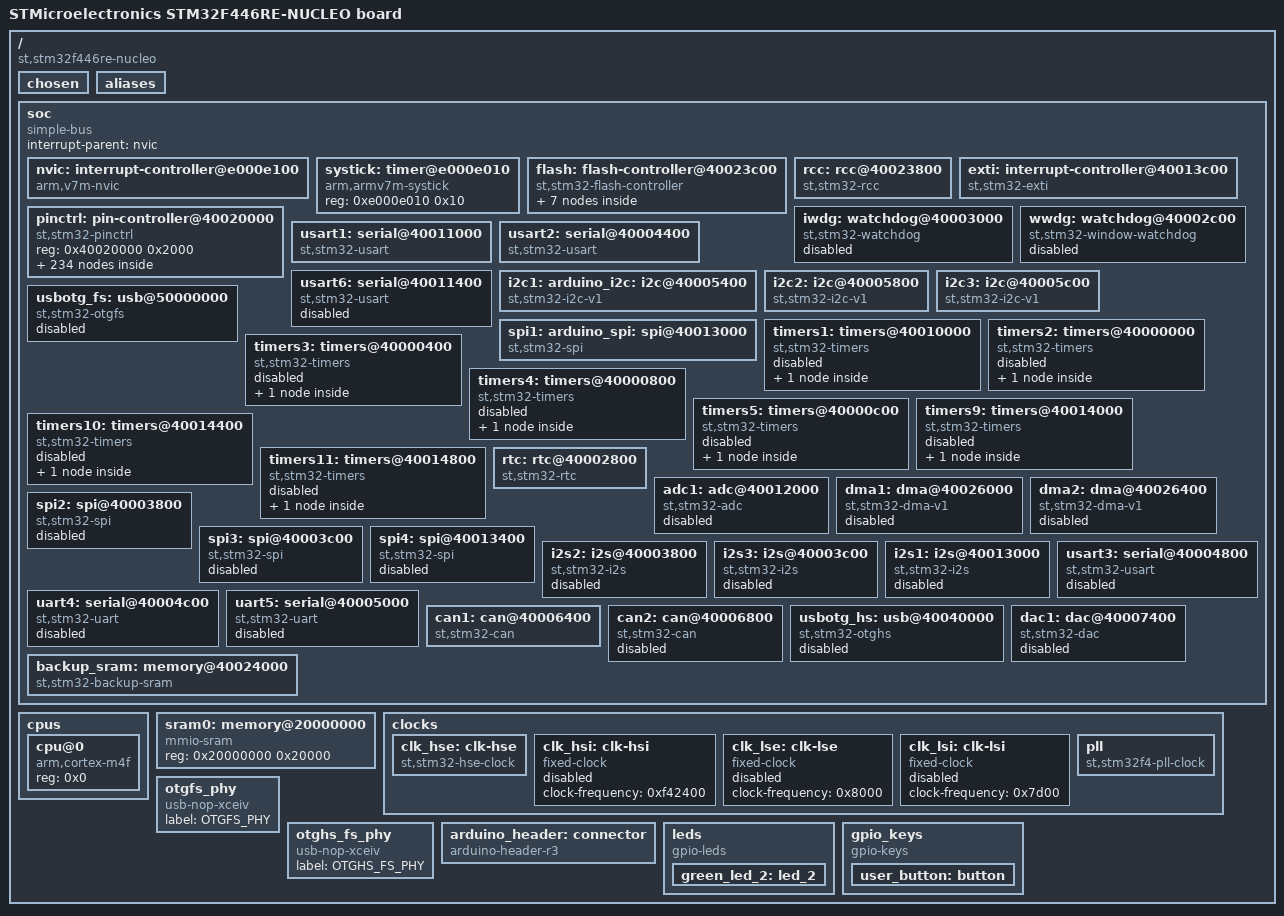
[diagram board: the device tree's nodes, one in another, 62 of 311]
/dts-v1/;

/ {
	#address-cells = < 0x1 >;
	#size-cells = < 0x1 >;
	model = "STMicroelectronics STM32F446RE-NUCLEO board";
	compatible = "st,stm32f446re-nucleo";
	chosen {
		zephyr,flash-controller = &flash;
		zephyr,console = &usart2;
		zephyr,shell-uart = &usart2;
		zephyr,sram = &sram0;
		zephyr,flash = &flash0;
		zephyr,can-primary = &can1;
	};
	aliases {
		led0 = &green_led_2;
		sw0 = &user_button;
	};
	soc {
		#address-cells = < 0x1 >;
		#size-cells = < 0x1 >;
		compatible = "simple-bus";
		interrupt-parent = < &nvic >;
		ranges;
		nvic: interrupt-controller@e000e100 {
			compatible = "arm,v7m-nvic";
			reg = < 0xe000e100 0xc00 >;
			interrupt-controller;
			#interrupt-cells = < 0x2 >;
			arm,num-irq-priority-bits = < 0x4 >;
			phandle = < 0x1 >;
		};
		systick: timer@e000e010 {
			compatible = "arm,armv7m-systick";
			reg = < 0xe000e010 0x10 >;
		};
		flash: flash-controller@40023c00 {
			compatible = "st,stm32-flash-controller", "st,stm32f4-flash-controller";
			label = "FLASH_CTRL";
			reg = < 0x40023c00 0x400 >;
			interrupts = < 0x4 0x0 >;
			#address-cells = < 0x1 >;
			#size-cells = < 0x1 >;
			flash0: flash@8000000 {
				compatible = "soc-nv-flash";
				label = "FLASH_STM32";
				write-block-size = < 0x1 >;
				reg = < 0x8000000 0x80000 >;
				partitions {
					compatible = "fixed-partitions";
					#address-cells = < 0x1 >;
					#size-cells = < 0x1 >;
					boot_partition: partition@0 {
						label = "mcuboot";
						reg = < 0x0 0x10000 >;
						read-only;
					};
					storage_partition: partition@10000 {
						label = "storage";
						reg = < 0x10000 0x10000 >;
					};
					slot0_partition: partition@20000 {
						label = "image-0";
						reg = < 0x20000 0x20000 >;
					};
					slot1_partition: partition@40000 {
						label = "image-1";
						reg = < 0x40000 0x20000 >;
					};
					scratch_partition: partition@60000 {
						label = "image-scratch";
						reg = < 0x60000 0x20000 >;
					};
				};
			};
		};
		rcc: rcc@40023800 {
			compatible = "st,stm32-rcc";
			#clock-cells = < 0x2 >;
			reg = < 0x40023800 0x400 >;
			clocks = < &pll >;
			clock-frequency = < 0x5b8d800 >;
			ahb-prescaler = < 0x1 >;
			apb1-prescaler = < 0x2 >;
			apb2-prescaler = < 0x1 >;
			phandle = < 0x3 >;
		};
		exti: interrupt-controller@40013c00 {
			compatible = "st,stm32-exti";
			interrupt-controller;
			#interrupt-cells = < 0x1 >;
			reg = < 0x40013c00 0x400 >;
		};
		pinctrl: pin-controller@40020000 {
			compatible = "st,stm32-pinctrl";
			#address-cells = < 0x1 >;
			#size-cells = < 0x1 >;
			reg = < 0x40020000 0x2000 >;
			gpioa: gpio@40020000 {
				compatible = "st,stm32-gpio";
				gpio-controller;
				#gpio-cells = < 0x2 >;
				reg = < 0x40020000 0x400 >;
				clocks = < &rcc 0x0 0x1 >;
				label = "GPIOA";
				phandle = < 0x1a >;
			};
			gpiob: gpio@40020400 {
				compatible = "st,stm32-gpio";
				gpio-controller;
				#gpio-cells = < 0x2 >;
				reg = < 0x40020400 0x400 >;
				clocks = < &rcc 0x0 0x2 >;
				label = "GPIOB";
				phandle = < 0xe >;
			};
			gpioc: gpio@40020800 {
				compatible = "st,stm32-gpio";
				gpio-controller;
				#gpio-cells = < 0x2 >;
				reg = < 0x40020800 0x400 >;
				clocks = < &rcc 0x0 0x4 >;
				label = "GPIOC";
				phandle = < 0x1b >;
			};
			gpiod: gpio@40020c00 {
				compatible = "st,stm32-gpio";
				gpio-controller;
				#gpio-cells = < 0x2 >;
				reg = < 0x40020c00 0x400 >;
				clocks = < &rcc 0x0 0x8 >;
				label = "GPIOD";
			};
			gpioe: gpio@40021000 {
				compatible = "st,stm32-gpio";
				gpio-controller;
				#gpio-cells = < 0x2 >;
				reg = < 0x40021000 0x400 >;
				clocks = < &rcc 0x0 0x10 >;
				label = "GPIOE";
			};
			gpioh: gpio@40021c00 {
				compatible = "st,stm32-gpio";
				gpio-controller;
				#gpio-cells = < 0x2 >;
				reg = < 0x40021c00 0x400 >;
				clocks = < &rcc 0x0 0x80 >;
				label = "GPIOH";
			};
			adc1_in0_pa0: adc1_in0_pa0 {
				pinmux = < 0x10 >;
			};
			adc1_in1_pa1: adc1_in1_pa1 {
				pinmux = < 0x110 >;
			};
			adc1_in2_pa2: adc1_in2_pa2 {
				pinmux = < 0x210 >;
			};
			adc1_in3_pa3: adc1_in3_pa3 {
				pinmux = < 0x310 >;
			};
			adc1_in4_pa4: adc1_in4_pa4 {
				pinmux = < 0x410 >;
			};
			adc1_in5_pa5: adc1_in5_pa5 {
				pinmux = < 0x510 >;
			};
			adc1_in6_pa6: adc1_in6_pa6 {
				pinmux = < 0x610 >;
			};
			adc1_in7_pa7: adc1_in7_pa7 {
				pinmux = < 0x710 >;
			};
			adc1_in8_pb0: adc1_in8_pb0 {
				pinmux = < 0x1010 >;
			};
			adc1_in9_pb1: adc1_in9_pb1 {
				pinmux = < 0x1110 >;
			};
			adc1_in10_pc0: adc1_in10_pc0 {
				pinmux = < 0x2010 >;
			};
			adc1_in11_pc1: adc1_in11_pc1 {
				pinmux = < 0x2110 >;
			};
			adc1_in12_pc2: adc1_in12_pc2 {
				pinmux = < 0x2210 >;
			};
			adc1_in13_pc3: adc1_in13_pc3 {
				pinmux = < 0x2310 >;
			};
			adc1_in14_pc4: adc1_in14_pc4 {
				pinmux = < 0x2410 >;
			};
			adc1_in15_pc5: adc1_in15_pc5 {
				pinmux = < 0x2510 >;
			};
			adc2_in0_pa0: adc2_in0_pa0 {
				pinmux = < 0x10 >;
			};
			adc2_in1_pa1: adc2_in1_pa1 {
				pinmux = < 0x110 >;
			};
			adc2_in2_pa2: adc2_in2_pa2 {
				pinmux = < 0x210 >;
			};
			adc2_in3_pa3: adc2_in3_pa3 {
				pinmux = < 0x310 >;
			};
			adc2_in4_pa4: adc2_in4_pa4 {
				pinmux = < 0x410 >;
			};
			adc2_in5_pa5: adc2_in5_pa5 {
				pinmux = < 0x510 >;
			};
			adc2_in6_pa6: adc2_in6_pa6 {
				pinmux = < 0x610 >;
			};
			adc2_in7_pa7: adc2_in7_pa7 {
				pinmux = < 0x710 >;
			};
			adc2_in8_pb0: adc2_in8_pb0 {
				pinmux = < 0x1010 >;
			};
			adc2_in9_pb1: adc2_in9_pb1 {
				pinmux = < 0x1110 >;
			};
			adc2_in10_pc0: adc2_in10_pc0 {
				pinmux = < 0x2010 >;
			};
			adc2_in11_pc1: adc2_in11_pc1 {
				pinmux = < 0x2110 >;
			};
			adc2_in12_pc2: adc2_in12_pc2 {
				pinmux = < 0x2210 >;
			};
			adc2_in13_pc3: adc2_in13_pc3 {
				pinmux = < 0x2310 >;
			};
			adc2_in14_pc4: adc2_in14_pc4 {
				pinmux = < 0x2410 >;
			};
			adc2_in15_pc5: adc2_in15_pc5 {
				pinmux = < 0x2510 >;
			};
			adc3_in0_pa0: adc3_in0_pa0 {
				pinmux = < 0x10 >;
			};
			adc3_in1_pa1: adc3_in1_pa1 {
				pinmux = < 0x110 >;
			};
			adc3_in2_pa2: adc3_in2_pa2 {
				pinmux = < 0x210 >;
			};
			adc3_in3_pa3: adc3_in3_pa3 {
				pinmux = < 0x310 >;
			};
			adc3_in10_pc0: adc3_in10_pc0 {
				pinmux = < 0x2010 >;
			};
			adc3_in11_pc1: adc3_in11_pc1 {
				pinmux = < 0x2110 >;
			};
			adc3_in12_pc2: adc3_in12_pc2 {
				pinmux = < 0x2210 >;
			};
			adc3_in13_pc3: adc3_in13_pc3 {
				pinmux = < 0x2310 >;
			};
			can1_rx_pa11: can1_rx_pa11 {
				pinmux = < 0xb09 >;
				bias-pull-up;
			};
			can1_rx_pb8: can1_rx_pb8 {
				pinmux = < 0x1809 >;
				bias-pull-up;
				phandle = < 0x16 >;
			};
			can2_rx_pb5: can2_rx_pb5 {
				pinmux = < 0x1509 >;
				bias-pull-up;
			};
			can2_rx_pb12: can2_rx_pb12 {
				pinmux = < 0x1c09 >;
				bias-pull-up;
			};
			can1_tx_pa12: can1_tx_pa12 {
				pinmux = < 0xc09 >;
			};
			can1_tx_pb9: can1_tx_pb9 {
				pinmux = < 0x1909 >;
				phandle = < 0x17 >;
			};
			can2_tx_pb6: can2_tx_pb6 {
				pinmux = < 0x1609 >;
			};
			can2_tx_pb13: can2_tx_pb13 {
				pinmux = < 0x1d09 >;
			};
			dac_out1_pa4: dac_out1_pa4 {
				pinmux = < 0x410 >;
			};
			dac_out2_pa5: dac_out2_pa5 {
				pinmux = < 0x510 >;
			};
			i2c1_scl_pb6: i2c1_scl_pb6 {
				pinmux = < 0x1604 >;
				bias-pull-up;
				drive-open-drain;
			};
			i2c1_scl_pb8: i2c1_scl_pb8 {
				pinmux = < 0x1804 >;
				bias-pull-up;
				drive-open-drain;
				phandle = < 0x8 >;
			};
			i2c2_scl_pb10: i2c2_scl_pb10 {
				pinmux = < 0x1a04 >;
				bias-pull-up;
				drive-open-drain;
				phandle = < 0xa >;
			};
			i2c3_scl_pa8: i2c3_scl_pa8 {
				pinmux = < 0x804 >;
				bias-pull-up;
				drive-open-drain;
				phandle = < 0xc >;
			};
			i2c1_sda_pb7: i2c1_sda_pb7 {
				pinmux = < 0x1704 >;
				bias-pull-up;
				drive-open-drain;
			};
			i2c1_sda_pb9: i2c1_sda_pb9 {
				pinmux = < 0x1904 >;
				bias-pull-up;
				drive-open-drain;
				phandle = < 0x9 >;
			};
			i2c2_sda_pb3: i2c2_sda_pb3 {
				pinmux = < 0x1304 >;
				bias-pull-up;
				drive-open-drain;
				phandle = < 0xb >;
			};
			i2c2_sda_pc12: i2c2_sda_pc12 {
				pinmux = < 0x2c04 >;
				bias-pull-up;
				drive-open-drain;
			};
			i2c3_sda_pb4: i2c3_sda_pb4 {
				pinmux = < 0x1404 >;
				bias-pull-up;
				drive-open-drain;
				phandle = < 0xd >;
			};
			i2c3_sda_pc9: i2c3_sda_pc9 {
				pinmux = < 0x2904 >;
				bias-pull-up;
				drive-open-drain;
			};
			i2s1_ck_pa5: i2s1_ck_pa5 {
				pinmux = < 0x505 >;
				slew-rate = "very-high-speed";
			};
			i2s1_ck_pb3: i2s1_ck_pb3 {
				pinmux = < 0x1305 >;
				slew-rate = "very-high-speed";
			};
			i2s2_ck_pa9: i2s2_ck_pa9 {
				pinmux = < 0x905 >;
				slew-rate = "very-high-speed";
			};
			i2s2_ck_pb10: i2s2_ck_pb10 {
				pinmux = < 0x1a05 >;
				slew-rate = "very-high-speed";
			};
			i2s2_ck_pb13: i2s2_ck_pb13 {
				pinmux = < 0x1d05 >;
				slew-rate = "very-high-speed";
			};
			i2s2_ck_pc7: i2s2_ck_pc7 {
				pinmux = < 0x2705 >;
				slew-rate = "very-high-speed";
			};
			i2s3_ck_pb3: i2s3_ck_pb3 {
				pinmux = < 0x1306 >;
				slew-rate = "very-high-speed";
			};
			i2s3_ck_pc10: i2s3_ck_pc10 {
				pinmux = < 0x2a06 >;
				slew-rate = "very-high-speed";
			};
			i2s1_sd_pa7: i2s1_sd_pa7 {
				pinmux = < 0x705 >;
			};
			i2s1_sd_pb5: i2s1_sd_pb5 {
				pinmux = < 0x1505 >;
			};
			i2s2_sd_pb15: i2s2_sd_pb15 {
				pinmux = < 0x1f05 >;
			};
			i2s2_sd_pc1: i2s2_sd_pc1 {
				pinmux = < 0x2107 >;
			};
			i2s2_sd_pc3: i2s2_sd_pc3 {
				pinmux = < 0x2305 >;
			};
			i2s3_sd_pb0: i2s3_sd_pb0 {
				pinmux = < 0x1007 >;
			};
			i2s3_sd_pb2: i2s3_sd_pb2 {
				pinmux = < 0x1207 >;
			};
			i2s3_sd_pb5: i2s3_sd_pb5 {
				pinmux = < 0x1506 >;
			};
			i2s3_sd_pc1: i2s3_sd_pc1 {
				pinmux = < 0x2105 >;
			};
			i2s3_sd_pc12: i2s3_sd_pc12 {
				pinmux = < 0x2c06 >;
			};
			i2s1_ws_pa4: i2s1_ws_pa4 {
				pinmux = < 0x405 >;
			};
			i2s1_ws_pa15: i2s1_ws_pa15 {
				pinmux = < 0xf05 >;
			};
			i2s2_ws_pb4: i2s2_ws_pb4 {
				pinmux = < 0x1407 >;
			};
			i2s2_ws_pb9: i2s2_ws_pb9 {
				pinmux = < 0x1905 >;
			};
			i2s2_ws_pb12: i2s2_ws_pb12 {
				pinmux = < 0x1c05 >;
			};
			i2s3_ws_pa4: i2s3_ws_pa4 {
				pinmux = < 0x406 >;
			};
			i2s3_ws_pa15: i2s3_ws_pa15 {
				pinmux = < 0xf06 >;
			};
			quadspi_bk1_io3_pa1: quadspi_bk1_io3_pa1 {
				pinmux = < 0x109 >;
				slew-rate = "very-high-speed";
			};
			quadspi_clk_pb2: quadspi_clk_pb2 {
				pinmux = < 0x1209 >;
				slew-rate = "very-high-speed";
			};
			quadspi_bk1_ncs_pb6: quadspi_bk1_ncs_pb6 {
				pinmux = < 0x160a >;
				slew-rate = "very-high-speed";
			};
			quadspi_bk1_io0_pc9: quadspi_bk1_io0_pc9 {
				pinmux = < 0x2909 >;
				slew-rate = "very-high-speed";
			};
			quadspi_bk1_io1_pc10: quadspi_bk1_io1_pc10 {
				pinmux = < 0x2a09 >;
				slew-rate = "very-high-speed";
			};
			quadspi_bk2_ncs_pc11: quadspi_bk2_ncs_pc11 {
				pinmux = < 0x2b09 >;
				slew-rate = "very-high-speed";
			};
			spi1_miso_pa6: spi1_miso_pa6 {
				pinmux = < 0x605 >;
				bias-pull-down;
				phandle = < 0x11 >;
			};
			spi1_miso_pb4: spi1_miso_pb4 {
				pinmux = < 0x1405 >;
				bias-pull-down;
			};
			spi2_miso_pb14: spi2_miso_pb14 {
				pinmux = < 0x1e05 >;
				bias-pull-down;
			};
			spi2_miso_pc2: spi2_miso_pc2 {
				pinmux = < 0x2205 >;
				bias-pull-down;
			};
			spi3_miso_pb4: spi3_miso_pb4 {
				pinmux = < 0x1406 >;
				bias-pull-down;
			};
			spi3_miso_pc11: spi3_miso_pc11 {
				pinmux = < 0x2b06 >;
				bias-pull-down;
			};
			spi1_mosi_pa7: spi1_mosi_pa7 {
				pinmux = < 0x705 >;
				bias-pull-down;
				phandle = < 0x12 >;
			};
			spi1_mosi_pb5: spi1_mosi_pb5 {
				pinmux = < 0x1505 >;
				bias-pull-down;
			};
			spi2_mosi_pb15: spi2_mosi_pb15 {
				pinmux = < 0x1f05 >;
				bias-pull-down;
			};
			spi2_mosi_pc1: spi2_mosi_pc1 {
				pinmux = < 0x2107 >;
				bias-pull-down;
			};
			spi2_mosi_pc3: spi2_mosi_pc3 {
				pinmux = < 0x2305 >;
				bias-pull-down;
			};
			spi3_mosi_pb0: spi3_mosi_pb0 {
				pinmux = < 0x1007 >;
				bias-pull-down;
			};
			spi3_mosi_pb2: spi3_mosi_pb2 {
				pinmux = < 0x1207 >;
				bias-pull-down;
			};
			spi3_mosi_pb5: spi3_mosi_pb5 {
				pinmux = < 0x1506 >;
				bias-pull-down;
			};
			spi3_mosi_pc1: spi3_mosi_pc1 {
				pinmux = < 0x2105 >;
				bias-pull-down;
			};
			spi3_mosi_pc12: spi3_mosi_pc12 {
				pinmux = < 0x2c06 >;
				bias-pull-down;
			};
			spi1_nss_pa4: spi1_nss_pa4 {
				pinmux = < 0x405 >;
				bias-pull-up;
				phandle = < 0xf >;
			};
			spi1_nss_pa15: spi1_nss_pa15 {
				pinmux = < 0xf05 >;
				bias-pull-up;
			};
			spi2_nss_pb4: spi2_nss_pb4 {
				pinmux = < 0x1407 >;
				bias-pull-up;
			};
			spi2_nss_pb9: spi2_nss_pb9 {
				pinmux = < 0x1905 >;
				bias-pull-up;
			};
			spi2_nss_pb12: spi2_nss_pb12 {
				pinmux = < 0x1c05 >;
				bias-pull-up;
			};
			spi3_nss_pa4: spi3_nss_pa4 {
				pinmux = < 0x406 >;
				bias-pull-up;
			};
			spi3_nss_pa15: spi3_nss_pa15 {
				pinmux = < 0xf06 >;
				bias-pull-up;
			};
			spi1_sck_pa5: spi1_sck_pa5 {
				pinmux = < 0x505 >;
				bias-pull-down;
				slew-rate = "very-high-speed";
				phandle = < 0x10 >;
			};
			spi1_sck_pb3: spi1_sck_pb3 {
				pinmux = < 0x1305 >;
				bias-pull-down;
				slew-rate = "very-high-speed";
			};
			spi2_sck_pa9: spi2_sck_pa9 {
				pinmux = < 0x905 >;
				bias-pull-down;
				slew-rate = "very-high-speed";
			};
			spi2_sck_pb10: spi2_sck_pb10 {
				pinmux = < 0x1a05 >;
				bias-pull-down;
				slew-rate = "very-high-speed";
			};
			spi2_sck_pb13: spi2_sck_pb13 {
				pinmux = < 0x1d05 >;
				bias-pull-down;
				slew-rate = "very-high-speed";
			};
			spi2_sck_pc7: spi2_sck_pc7 {
				pinmux = < 0x2705 >;
				bias-pull-down;
				slew-rate = "very-high-speed";
			};
			spi3_sck_pb3: spi3_sck_pb3 {
				pinmux = < 0x1306 >;
				bias-pull-down;
				slew-rate = "very-high-speed";
			};
			spi3_sck_pc10: spi3_sck_pc10 {
				pinmux = < 0x2a06 >;
				bias-pull-down;
				slew-rate = "very-high-speed";
			};
			tim10_ch1_pb8: tim10_ch1_pb8 {
				pinmux = < 0x1803 >;
			};
			tim1_ch1n_pa7: tim1_ch1n_pa7 {
				pinmux = < 0x701 >;
			};
			tim1_ch1_pa8: tim1_ch1_pa8 {
				pinmux = < 0x801 >;
			};
			tim1_ch2_pa9: tim1_ch2_pa9 {
				pinmux = < 0x901 >;
			};
			tim1_ch3_pa10: tim1_ch3_pa10 {
				pinmux = < 0xa01 >;
			};
			tim1_ch4_pa11: tim1_ch4_pa11 {
				pinmux = < 0xb01 >;
			};
			tim1_ch2n_pb0: tim1_ch2n_pb0 {
				pinmux = < 0x1001 >;
			};
			tim1_ch3n_pb1: tim1_ch3n_pb1 {
				pinmux = < 0x1101 >;
			};
			tim11_ch1_pb9: tim11_ch1_pb9 {
				pinmux = < 0x1903 >;
			};
			tim1_ch1n_pb13: tim1_ch1n_pb13 {
				pinmux = < 0x1d01 >;
			};
			tim1_ch2n_pb14: tim1_ch2n_pb14 {
				pinmux = < 0x1e01 >;
			};
			tim1_ch3n_pb15: tim1_ch3n_pb15 {
				pinmux = < 0x1f01 >;
			};
			tim2_ch1_pa0: tim2_ch1_pa0 {
				pinmux = < 0x1 >;
			};
			tim2_ch2_pa1: tim2_ch2_pa1 {
				pinmux = < 0x101 >;
			};
			tim2_ch3_pa2: tim2_ch3_pa2 {
				pinmux = < 0x201 >;
			};
			tim2_ch4_pa3: tim2_ch4_pa3 {
				pinmux = < 0x301 >;
			};
			tim2_ch1_pa5: tim2_ch1_pa5 {
				pinmux = < 0x501 >;
			};
			tim2_ch1_pa15: tim2_ch1_pa15 {
				pinmux = < 0xf01 >;
			};
			tim2_ch4_pb2: tim2_ch4_pb2 {
				pinmux = < 0x1201 >;
			};
			tim2_ch2_pb3: tim2_ch2_pb3 {
				pinmux = < 0x1301 >;
			};
			tim2_ch1_pb8: tim2_ch1_pb8 {
				pinmux = < 0x1801 >;
			};
			tim2_ch2_pb9: tim2_ch2_pb9 {
				pinmux = < 0x1901 >;
			};
			tim2_ch3_pb10: tim2_ch3_pb10 {
				pinmux = < 0x1a01 >;
			};
			tim12_ch1_pb14: tim12_ch1_pb14 {
				pinmux = < 0x1e09 >;
			};
			tim12_ch2_pb15: tim12_ch2_pb15 {
				pinmux = < 0x1f09 >;
			};
			tim13_ch1_pa6: tim13_ch1_pa6 {
				pinmux = < 0x609 >;
			};
			tim3_ch1_pa6: tim3_ch1_pa6 {
				pinmux = < 0x602 >;
			};
			tim3_ch2_pa7: tim3_ch2_pa7 {
				pinmux = < 0x702 >;
			};
			tim3_ch3_pb0: tim3_ch3_pb0 {
				pinmux = < 0x1002 >;
			};
			tim3_ch4_pb1: tim3_ch4_pb1 {
				pinmux = < 0x1102 >;
			};
			tim3_ch1_pb4: tim3_ch1_pb4 {
				pinmux = < 0x1402 >;
			};
			tim3_ch2_pb5: tim3_ch2_pb5 {
				pinmux = < 0x1502 >;
			};
			tim3_ch1_pc6: tim3_ch1_pc6 {
				pinmux = < 0x2602 >;
			};
			tim3_ch2_pc7: tim3_ch2_pc7 {
				pinmux = < 0x2702 >;
			};
			tim3_ch3_pc8: tim3_ch3_pc8 {
				pinmux = < 0x2802 >;
			};
			tim3_ch4_pc9: tim3_ch4_pc9 {
				pinmux = < 0x2902 >;
			};
			tim14_ch1_pa7: tim14_ch1_pa7 {
				pinmux = < 0x709 >;
			};
			tim4_ch1_pb6: tim4_ch1_pb6 {
				pinmux = < 0x1602 >;
			};
			tim4_ch2_pb7: tim4_ch2_pb7 {
				pinmux = < 0x1702 >;
			};
			tim4_ch3_pb8: tim4_ch3_pb8 {
				pinmux = < 0x1802 >;
			};
			tim4_ch4_pb9: tim4_ch4_pb9 {
				pinmux = < 0x1902 >;
			};
			tim5_ch1_pa0: tim5_ch1_pa0 {
				pinmux = < 0x2 >;
			};
			tim5_ch2_pa1: tim5_ch2_pa1 {
				pinmux = < 0x102 >;
			};
			tim5_ch3_pa2: tim5_ch3_pa2 {
				pinmux = < 0x202 >;
			};
			tim5_ch4_pa3: tim5_ch4_pa3 {
				pinmux = < 0x302 >;
			};
			tim8_ch1n_pa5: tim8_ch1n_pa5 {
				pinmux = < 0x503 >;
			};
			tim8_ch1n_pa7: tim8_ch1n_pa7 {
				pinmux = < 0x703 >;
			};
			tim8_ch2n_pb0: tim8_ch2n_pb0 {
				pinmux = < 0x1003 >;
			};
			tim8_ch3n_pb1: tim8_ch3n_pb1 {
				pinmux = < 0x1103 >;
			};
			tim8_ch2n_pb14: tim8_ch2n_pb14 {
				pinmux = < 0x1e03 >;
			};
			tim8_ch3n_pb15: tim8_ch3n_pb15 {
				pinmux = < 0x1f03 >;
			};
			tim8_ch1_pc6: tim8_ch1_pc6 {
				pinmux = < 0x2603 >;
			};
			tim8_ch2_pc7: tim8_ch2_pc7 {
				pinmux = < 0x2703 >;
			};
			tim8_ch3_pc8: tim8_ch3_pc8 {
				pinmux = < 0x2803 >;
			};
			tim8_ch4_pc9: tim8_ch4_pc9 {
				pinmux = < 0x2903 >;
			};
			tim9_ch1_pa2: tim9_ch1_pa2 {
				pinmux = < 0x203 >;
			};
			tim9_ch2_pa3: tim9_ch2_pa3 {
				pinmux = < 0x303 >;
			};
			usart1_cts_pa11: usart1_cts_pa11 {
				pinmux = < 0xb07 >;
				bias-pull-up;
				drive-open-drain;
			};
			usart2_cts_pa0: usart2_cts_pa0 {
				pinmux = < 0x7 >;
				bias-pull-up;
				drive-open-drain;
			};
			usart3_cts_pb13: usart3_cts_pb13 {
				pinmux = < 0x1d07 >;
				bias-pull-up;
				drive-open-drain;
			};
			uart4_cts_pb0: uart4_cts_pb0 {
				pinmux = < 0x1008 >;
				bias-pull-up;
				drive-open-drain;
			};
			uart5_cts_pc9: uart5_cts_pc9 {
				pinmux = < 0x2907 >;
				bias-pull-up;
				drive-open-drain;
			};
			usart1_rts_pa12: usart1_rts_pa12 {
				pinmux = < 0xc07 >;
				bias-pull-up;
				drive-open-drain;
			};
			usart2_rts_pa1: usart2_rts_pa1 {
				pinmux = < 0x107 >;
				bias-pull-up;
				drive-open-drain;
			};
			usart3_rts_pb14: usart3_rts_pb14 {
				pinmux = < 0x1e07 >;
				bias-pull-up;
				drive-open-drain;
			};
			uart4_rts_pa15: uart4_rts_pa15 {
				pinmux = < 0xf08 >;
				bias-pull-up;
				drive-open-drain;
			};
			uart5_rts_pc8: uart5_rts_pc8 {
				pinmux = < 0x2807 >;
				bias-pull-up;
				drive-open-drain;
			};
			usart1_rx_pa10: usart1_rx_pa10 {
				pinmux = < 0xa07 >;
				phandle = < 0x5 >;
			};
			usart1_rx_pb7: usart1_rx_pb7 {
				pinmux = < 0x1707 >;
			};
			usart2_rx_pa3: usart2_rx_pa3 {
				pinmux = < 0x307 >;
				phandle = < 0x7 >;
			};
			usart3_rx_pc5: usart3_rx_pc5 {
				pinmux = < 0x2507 >;
			};
			usart3_rx_pc11: usart3_rx_pc11 {
				pinmux = < 0x2b07 >;
			};
			uart4_rx_pa1: uart4_rx_pa1 {
				pinmux = < 0x108 >;
			};
			uart4_rx_pc11: uart4_rx_pc11 {
				pinmux = < 0x2b08 >;
			};
			uart5_rx_pd2: uart5_rx_pd2 {
				pinmux = < 0x3208 >;
			};
			usart6_rx_pc7: usart6_rx_pc7 {
				pinmux = < 0x2708 >;
			};
			usart1_tx_pa9: usart1_tx_pa9 {
				pinmux = < 0x907 >;
				bias-pull-up;
				phandle = < 0x4 >;
			};
			usart1_tx_pb6: usart1_tx_pb6 {
				pinmux = < 0x1607 >;
				bias-pull-up;
			};
			usart2_tx_pa2: usart2_tx_pa2 {
				pinmux = < 0x207 >;
				bias-pull-up;
				phandle = < 0x6 >;
			};
			usart3_tx_pb10: usart3_tx_pb10 {
				pinmux = < 0x1a07 >;
				bias-pull-up;
			};
			usart3_tx_pc10: usart3_tx_pc10 {
				pinmux = < 0x2a07 >;
				bias-pull-up;
			};
			uart4_tx_pa0: uart4_tx_pa0 {
				pinmux = < 0x8 >;
				bias-pull-up;
			};
			uart4_tx_pc10: uart4_tx_pc10 {
				pinmux = < 0x2a08 >;
				bias-pull-up;
			};
			uart5_tx_pc12: uart5_tx_pc12 {
				pinmux = < 0x2c08 >;
				bias-pull-up;
			};
			usart6_tx_pc6: usart6_tx_pc6 {
				pinmux = < 0x2608 >;
				bias-pull-up;
			};
			usb_otg_fs_sof_pa8: usb_otg_fs_sof_pa8 {
				pinmux = < 0x80a >;
			};
			usb_otg_fs_vbus_pa9: usb_otg_fs_vbus_pa9 {
				pinmux = < 0x910 >;
			};
			usb_otg_fs_id_pa10: usb_otg_fs_id_pa10 {
				pinmux = < 0xa0a >;
			};
			usb_otg_fs_dm_pa11: usb_otg_fs_dm_pa11 {
				pinmux = < 0xb0a >;
			};
			usb_otg_fs_dp_pa12: usb_otg_fs_dp_pa12 {
				pinmux = < 0xc0a >;
			};
			usb_otg_hs_sof_pa4: usb_otg_hs_sof_pa4 {
				pinmux = < 0x40c >;
			};
			usb_otg_hs_id_pb12: usb_otg_hs_id_pb12 {
				pinmux = < 0x1c0c >;
			};
			usb_otg_hs_vbus_pb13: usb_otg_hs_vbus_pb13 {
				pinmux = < 0x1d10 >;
			};
			usb_otg_hs_dm_pb14: usb_otg_hs_dm_pb14 {
				pinmux = < 0x1e0c >;
			};
			usb_otg_hs_dp_pb15: usb_otg_hs_dp_pb15 {
				pinmux = < 0x1f0c >;
			};
			usb_otg_hs_ulpi_d0_pa3: usb_otg_hs_ulpi_d0_pa3 {
				pinmux = < 0x30a >;
			};
			usb_otg_hs_ulpi_d1_pb0: usb_otg_hs_ulpi_d1_pb0 {
				pinmux = < 0x100a >;
			};
			usb_otg_hs_ulpi_d2_pb1: usb_otg_hs_ulpi_d2_pb1 {
				pinmux = < 0x110a >;
			};
			usb_otg_hs_ulpi_d4_pb2: usb_otg_hs_ulpi_d4_pb2 {
				pinmux = < 0x120a >;
			};
			usb_otg_hs_ulpi_d7_pb5: usb_otg_hs_ulpi_d7_pb5 {
				pinmux = < 0x150a >;
			};
			usb_otg_hs_ulpi_d3_pb10: usb_otg_hs_ulpi_d3_pb10 {
				pinmux = < 0x1a0a >;
			};
			usb_otg_hs_ulpi_d5_pb12: usb_otg_hs_ulpi_d5_pb12 {
				pinmux = < 0x1c0a >;
			};
			usb_otg_hs_ulpi_d6_pb13: usb_otg_hs_ulpi_d6_pb13 {
				pinmux = < 0x1d0a >;
			};
			usb_otg_hs_ulpi_stp_pc0: usb_otg_hs_ulpi_stp_pc0 {
				pinmux = < 0x200a >;
			};
			usb_otg_hs_ulpi_dir_pc2: usb_otg_hs_ulpi_dir_pc2 {
				pinmux = < 0x220a >;
			};
			usb_otg_hs_ulpi_nxt_pc3: usb_otg_hs_ulpi_nxt_pc3 {
				pinmux = < 0x230a >;
			};
		};
		iwdg: watchdog@40003000 {
			compatible = "st,stm32-watchdog";
			reg = < 0x40003000 0x400 >;
			label = "IWDG";
			status = "disabled";
		};
		wwdg: watchdog@40002c00 {
			compatible = "st,stm32-window-watchdog";
			reg = < 0x40002c00 0x400 >;
			clocks = < &rcc 0x2 0x800 >;
			label = "WWDG";
			interrupts = < 0x0 0x7 >;
			status = "disabled";
		};
		usart1: serial@40011000 {
			compatible = "st,stm32-usart", "st,stm32-uart";
			reg = < 0x40011000 0x400 >;
			clocks = < &rcc 0x3 0x10 >;
			interrupts = < 0x25 0x0 >;
			status = "okay";
			label = "UART_1";
			pinctrl-0 = < &usart1_tx_pa9 &usart1_rx_pa10 >;
			current-speed = < 0x1c200 >;
		};
		usart2: serial@40004400 {
			compatible = "st,stm32-usart", "st,stm32-uart";
			reg = < 0x40004400 0x400 >;
			clocks = < &rcc 0x2 0x20000 >;
			interrupts = < 0x26 0x0 >;
			status = "okay";
			label = "UART_2";
			pinctrl-0 = < &usart2_tx_pa2 &usart2_rx_pa3 >;
			current-speed = < 0x1c200 >;
		};
		usart6: serial@40011400 {
			compatible = "st,stm32-usart", "st,stm32-uart";
			reg = < 0x40011400 0x400 >;
			clocks = < &rcc 0x3 0x20 >;
			interrupts = < 0x47 0x0 >;
			status = "disabled";
			label = "UART_6";
		};
		i2c1: arduino_i2c: i2c@40005400 {
			compatible = "st,stm32-i2c-v1";
			clock-frequency = < 0x61a80 >;
			#address-cells = < 0x1 >;
			#size-cells = < 0x0 >;
			reg = < 0x40005400 0x400 >;
			clocks = < &rcc 0x2 0x200000 >;
			interrupts = < 0x1f 0x0 >, < 0x20 0x0 >;
			interrupt-names = "event", "error";
			status = "okay";
			label = "I2C_1";
			pinctrl-0 = < &i2c1_scl_pb8 &i2c1_sda_pb9 >;
		};
		i2c2: i2c@40005800 {
			compatible = "st,stm32-i2c-v1";
			clock-frequency = < 0x61a80 >;
			#address-cells = < 0x1 >;
			#size-cells = < 0x0 >;
			reg = < 0x40005800 0x400 >;
			clocks = < &rcc 0x2 0x400000 >;
			interrupts = < 0x21 0x0 >, < 0x22 0x0 >;
			interrupt-names = "event", "error";
			status = "okay";
			label = "I2C_2";
			pinctrl-0 = < &i2c2_scl_pb10 &i2c2_sda_pb3 >;
		};
		i2c3: i2c@40005c00 {
			compatible = "st,stm32-i2c-v1";
			clock-frequency = < 0x61a80 >;
			#address-cells = < 0x1 >;
			#size-cells = < 0x0 >;
			reg = < 0x40005c00 0x400 >;
			clocks = < &rcc 0x2 0x800000 >;
			interrupts = < 0x48 0x0 >, < 0x49 0x0 >;
			interrupt-names = "event", "error";
			status = "okay";
			label = "I2C_3";
			pinctrl-0 = < &i2c3_scl_pa8 &i2c3_sda_pb4 >;
		};
		spi1: arduino_spi: spi@40013000 {
			compatible = "st,stm32-spi";
			#address-cells = < 0x1 >;
			#size-cells = < 0x0 >;
			reg = < 0x40013000 0x400 >;
			clocks = < &rcc 0x3 0x1000 >;
			interrupts = < 0x23 0x5 >;
			status = "okay";
			label = "SPI_1";
			cs-gpios = < &gpiob 0x6 0x1 >;
			pinctrl-0 = < &spi1_nss_pa4 &spi1_sck_pa5 &spi1_miso_pa6 &spi1_mosi_pa7 >;
		};
		usbotg_fs: usb@50000000 {
			compatible = "st,stm32-otgfs";
			reg = < 0x50000000 0x40000 >;
			interrupts = < 0x43 0x0 >;
			interrupt-names = "otgfs";
			num-bidir-endpoints = < 0x6 >;
			ram-size = < 0x500 >;
			maximum-speed = "full-speed";
			phys = < &otgfs_phy >;
			clocks = < &rcc 0x1 0x80 >;
			status = "disabled";
			label = "OTGFS";
		};
		timers1: timers@40010000 {
			compatible = "st,stm32-timers";
			reg = < 0x40010000 0x400 >;
			clocks = < &rcc 0x3 0x1 >;
			interrupts = < 0x18 0x0 >, < 0x19 0x0 >, < 0x1a 0x0 >, < 0x1b 0x0 >;
			interrupt-names = "brk", "up", "trgcom", "cc";
			status = "disabled";
			label = "TIMERS_1";
			pwm {
				compatible = "st,stm32-pwm";
				status = "disabled";
				st,prescaler = < 0x2710 >;
				label = "PWM_1";
				#pwm-cells = < 0x3 >;
			};
		};
		timers2: timers@40000000 {
			compatible = "st,stm32-timers";
			reg = < 0x40000000 0x400 >;
			clocks = < &rcc 0x2 0x1 >;
			interrupts = < 0x1c 0x0 >;
			interrupt-names = "global";
			status = "disabled";
			label = "TIMERS_2";
			pwm {
				compatible = "st,stm32-pwm";
				status = "disabled";
				st,prescaler = < 0x0 >;
				label = "PWM_2";
				#pwm-cells = < 0x3 >;
			};
		};
		timers3: timers@40000400 {
			compatible = "st,stm32-timers";
			reg = < 0x40000400 0x400 >;
			clocks = < &rcc 0x2 0x2 >;
			interrupts = < 0x1d 0x0 >;
			interrupt-names = "global";
			status = "disabled";
			label = "TIMERS_3";
			pwm {
				compatible = "st,stm32-pwm";
				status = "disabled";
				st,prescaler = < 0x2710 >;
				label = "PWM_3";
				#pwm-cells = < 0x3 >;
			};
		};
		timers4: timers@40000800 {
			compatible = "st,stm32-timers";
			reg = < 0x40000800 0x400 >;
			clocks = < &rcc 0x2 0x4 >;
			interrupts = < 0x1e 0x0 >;
			interrupt-names = "global";
			status = "disabled";
			label = "TIMERS_4";
			pwm {
				compatible = "st,stm32-pwm";
				status = "disabled";
				st,prescaler = < 0x2710 >;
				label = "PWM_4";
				#pwm-cells = < 0x3 >;
			};
		};
		timers5: timers@40000c00 {
			compatible = "st,stm32-timers";
			reg = < 0x40000c00 0x400 >;
			clocks = < &rcc 0x2 0x8 >;
			interrupts = < 0x32 0x0 >;
			interrupt-names = "global";
			status = "disabled";
			label = "TIMERS_5";
			pwm {
				compatible = "st,stm32-pwm";
				status = "disabled";
				st,prescaler = < 0x0 >;
				label = "PWM_5";
				#pwm-cells = < 0x3 >;
			};
		};
		timers9: timers@40014000 {
			compatible = "st,stm32-timers";
			reg = < 0x40014000 0x400 >;
			clocks = < &rcc 0x3 0x10000 >;
			interrupts = < 0x18 0x0 >;
			interrupt-names = "global";
			status = "disabled";
			label = "TIMERS_9";
			pwm {
				compatible = "st,stm32-pwm";
				status = "disabled";
				st,prescaler = < 0x2710 >;
				label = "PWM_9";
				#pwm-cells = < 0x3 >;
			};
		};
		timers10: timers@40014400 {
			compatible = "st,stm32-timers";
			reg = < 0x40014400 0x400 >;
			clocks = < &rcc 0x3 0x20000 >;
			interrupts = < 0x19 0x0 >;
			interrupt-names = "global";
			status = "disabled";
			label = "TIMERS_10";
			pwm {
				compatible = "st,stm32-pwm";
				status = "disabled";
				st,prescaler = < 0x2710 >;
				label = "PWM_10";
				#pwm-cells = < 0x3 >;
			};
		};
		timers11: timers@40014800 {
			compatible = "st,stm32-timers";
			reg = < 0x40014800 0x400 >;
			clocks = < &rcc 0x3 0x40000 >;
			interrupts = < 0x1a 0x0 >;
			interrupt-names = "global";
			status = "disabled";
			label = "TIMERS_11";
			pwm {
				compatible = "st,stm32-pwm";
				status = "disabled";
				st,prescaler = < 0x2710 >;
				label = "PWM_11";
				#pwm-cells = < 0x3 >;
			};
		};
		rtc: rtc@40002800 {
			compatible = "st,stm32-rtc";
			reg = < 0x40002800 0x400 >;
			interrupts = < 0x29 0x0 >;
			clocks = < &rcc 0x2 0x10000000 >;
			prescaler = < 0x8000 >;
			status = "okay";
			label = "RTC_0";
		};
		adc1: adc@40012000 {
			compatible = "st,stm32-adc";
			reg = < 0x40012000 0x400 >;
			clocks = < &rcc 0x3 0x100 >;
			interrupts = < 0x12 0x0 >;
			status = "disabled";
			label = "ADC_1";
			#io-channel-cells = < 0x1 >;
		};
		dma1: dma@40026000 {
			compatible = "st,stm32-dma-v1";
			#dma-cells = < 0x4 >;
			reg = < 0x40026000 0x400 >;
			interrupts = < 0xb 0x0 0xc 0x0 0xd 0x0 0xe 0x0 0xf 0x0 0x10 0x0 0x11 0x0 0x2f 0x0 >;
			clocks = < &rcc 0x0 0x200000 >;
			status = "disabled";
			label = "DMA_1";
			phandle = < 0x14 >;
		};
		dma2: dma@40026400 {
			compatible = "st,stm32-dma-v1";
			#dma-cells = < 0x4 >;
			reg = < 0x40026400 0x400 >;
			interrupts = < 0x38 0x0 0x39 0x0 0x3a 0x0 0x3b 0x0 0x3c 0x0 0x44 0x0 0x45 0x0 0x46 0x0 >;
			clocks = < &rcc 0x0 0x400000 >;
			st,mem2mem;
			status = "disabled";
			label = "DMA_2";
			phandle = < 0x15 >;
		};
		spi2: spi@40003800 {
			compatible = "st,stm32-spi";
			#address-cells = < 0x1 >;
			#size-cells = < 0x0 >;
			reg = < 0x40003800 0x400 >;
			clocks = < &rcc 0x2 0x4000 >;
			interrupts = < 0x24 0x5 >;
			status = "disabled";
			label = "SPI_2";
		};
		spi3: spi@40003c00 {
			compatible = "st,stm32-spi";
			#address-cells = < 0x1 >;
			#size-cells = < 0x0 >;
			reg = < 0x40003c00 0x400 >;
			clocks = < &rcc 0x2 0x8000 >;
			interrupts = < 0x33 0x5 >;
			status = "disabled";
			label = "SPI_3";
		};
		spi4: spi@40013400 {
			compatible = "st,stm32-spi";
			#address-cells = < 0x1 >;
			#size-cells = < 0x0 >;
			reg = < 0x40013400 0x400 >;
			clocks = < &rcc 0x3 0x2000 >;
			interrupts = < 0x54 0x5 >;
			status = "disabled";
			label = "SPI_4";
		};
		i2s2: i2s@40003800 {
			compatible = "st,stm32-i2s";
			#address-cells = < 0x1 >;
			#size-cells = < 0x0 >;
			reg = < 0x40003800 0x400 >;
			clocks = < &rcc 0x2 0x4000 >;
			interrupts = < 0x24 0x5 >;
			dmas = < &dma1 0x4 0x0 0x400 0x3 &dma1 0x3 0x0 0x400 0x3 >;
			dma-names = "tx", "rx";
			status = "disabled";
			label = "I2S_2";
		};
		i2s3: i2s@40003c00 {
			compatible = "st,stm32-i2s";
			#address-cells = < 0x1 >;
			#size-cells = < 0x0 >;
			reg = < 0x40003c00 0x400 >;
			clocks = < &rcc 0x2 0x8000 >;
			interrupts = < 0x33 0x5 >;
			dmas = < &dma1 0x5 0x0 0x400 0x3 &dma1 0x0 0x0 0x400 0x3 >;
			dma-names = "tx", "rx";
			status = "disabled";
			label = "I2S_3";
		};
		i2s1: i2s@40013000 {
			compatible = "st,stm32-i2s";
			#address-cells = < 0x1 >;
			#size-cells = < 0x0 >;
			reg = < 0x40013000 0x400 >;
			clocks = < &rcc 0x3 0x1000 >;
			interrupts = < 0x23 0x5 >;
			dmas = < &dma2 0x3 0x3 0x400 0x3 &dma2 0x2 0x3 0x400 0x3 >;
			dma-names = "tx", "rx";
			status = "disabled";
			label = "I2S_1";
		};
		usart3: serial@40004800 {
			compatible = "st,stm32-usart", "st,stm32-uart";
			reg = < 0x40004800 0x400 >;
			clocks = < &rcc 0x2 0x40000 >;
			interrupts = < 0x27 0x0 >;
			status = "disabled";
			label = "UART_3";
		};
		uart4: serial@40004c00 {
			compatible = "st,stm32-uart";
			reg = < 0x40004c00 0x400 >;
			clocks = < &rcc 0x2 0x80000 >;
			interrupts = < 0x34 0x0 >;
			status = "disabled";
			label = "UART_4";
		};
		uart5: serial@40005000 {
			compatible = "st,stm32-uart";
			reg = < 0x40005000 0x400 >;
			clocks = < &rcc 0x2 0x100000 >;
			interrupts = < 0x35 0x0 >;
			status = "disabled";
			label = "UART_5";
		};
		can1: can@40006400 {
			compatible = "st,stm32-can";
			#address-cells = < 0x1 >;
			#size-cells = < 0x0 >;
			reg = < 0x40006400 0x400 >;
			interrupts = < 0x13 0x0 >, < 0x14 0x0 >, < 0x15 0x0 >, < 0x16 0x0 >;
			interrupt-names = "TX", "RX0", "RX1", "SCE";
			clocks = < &rcc 0x2 0x2000000 >;
			status = "okay";
			label = "CAN_1";
			bus-speed = < 0x1e848 >;
			sjw = < 0x1 >;
			prop-seg = < 0x0 >;
			phase-seg1 = < 0x6 >;
			phase-seg2 = < 0x5 >;
			pinctrl-0 = < &can1_rx_pb8 &can1_tx_pb9 >;
		};
		can2: can@40006800 {
			compatible = "st,stm32-can";
			#address-cells = < 0x1 >;
			#size-cells = < 0x0 >;
			reg = < 0x40006800 0x400 >;
			interrupts = < 0x3f 0x0 >, < 0x40 0x0 >, < 0x41 0x0 >, < 0x42 0x0 >;
			interrupt-names = "TX", "RX0", "RX1", "SCE";
			clocks = < &rcc 0x2 0x4000000 >;
			master-can-reg = < 0x40006400 >;
			status = "disabled";
			label = "CAN_2";
			bus-speed = < 0x1e848 >;
			sjw = < 0x1 >;
			prop-seg = < 0x0 >;
			phase-seg1 = < 0x5 >;
			phase-seg2 = < 0x6 >;
		};
		usbotg_hs: usb@40040000 {
			compatible = "st,stm32-otghs";
			reg = < 0x40040000 0x40000 >;
			interrupts = < 0x4d 0x0 >, < 0x4a 0x0 >, < 0x4b 0x0 >;
			interrupt-names = "otghs", "ep1_out", "ep1_in";
			num-bidir-endpoints = < 0x9 >;
			ram-size = < 0x1000 >;
			maximum-speed = "full-speed";
			phys = < &otghs_fs_phy >;
			clocks = < &rcc 0x0 0x20000000 >;
			status = "disabled";
			label = "OTGHS";
		};
		backup_sram: memory@40024000 {
			compatible = "st,stm32-backup-sram";
			reg = < 0x40024000 0x1000 >;
			clocks = < &rcc 0x0 0x40000 >;
			label = "BACKUP_SRAM";
			status = "okay";
		};
		dac1: dac@40007400 {
			compatible = "st,stm32-dac";
			reg = < 0x40007400 0x400 >;
			clocks = < &rcc 0x2 0x20000000 >;
			status = "disabled";
			label = "DAC_1";
			#io-channel-cells = < 0x1 >;
		};
	};
	cpus {
		#address-cells = < 0x1 >;
		#size-cells = < 0x0 >;
		cpu@0 {
			device_type = "cpu";
			compatible = "arm,cortex-m4f";
			reg = < 0x0 >;
		};
	};
	sram0: memory@20000000 {
		compatible = "mmio-sram";
		reg = < 0x20000000 0x20000 >;
	};
	clocks {
		clk_hse: clk-hse {
			#clock-cells = < 0x0 >;
			compatible = "st,stm32-hse-clock";
			status = "okay";
			hse-bypass;
			clock-frequency = < 0x7a1200 >;
			phandle = < 0x19 >;
		};
		clk_hsi: clk-hsi {
			#clock-cells = < 0x0 >;
			compatible = "fixed-clock";
			clock-frequency = < 0xf42400 >;
			status = "disabled";
		};
		clk_lse: clk-lse {
			#clock-cells = < 0x0 >;
			compatible = "fixed-clock";
			clock-frequency = < 0x8000 >;
			status = "disabled";
		};
		clk_lsi: clk-lsi {
			#clock-cells = < 0x0 >;
			compatible = "fixed-clock";
			clock-frequency = < 0x7d00 >;
			status = "disabled";
		};
		pll: pll {
			#clock-cells = < 0x0 >;
			compatible = "st,stm32f4-pll-clock";
			status = "okay";
			div-m = < 0x8 >;
			mul-n = < 0x180 >;
			div-p = < 0x4 >;
			div-q = < 0x8 >;
			clocks = < &clk_hse >;
			phandle = < 0x2 >;
		};
	};
	otgfs_phy: otgfs_phy {
		compatible = "usb-nop-xceiv";
		#phy-cells = < 0x0 >;
		label = "OTGFS_PHY";
		phandle = < 0x13 >;
	};
	otghs_fs_phy: otghs_fs_phy {
		compatible = "usb-nop-xceiv";
		#phy-cells = < 0x0 >;
		label = "OTGHS_FS_PHY";
		phandle = < 0x18 >;
	};
	arduino_header: connector {
		compatible = "arduino-header-r3";
		#gpio-cells = < 0x2 >;
		gpio-map-mask = < 0xffffffff 0xffffffc0 >;
		gpio-map-pass-thru = < 0x0 0x3f >;
		gpio-map = < 0x0 0x0 &gpioa 0x0 0x0 >, < 0x1 0x0 &gpioa 0x1 0x0 >, < 0x2 0x0 &gpioa 0x4 0x0 >, < 0x3 0x0 &gpiob 0x0 0x0 >, < 0x4 0x0 &gpioc 0x1 0x0 >, < 0x5 0x0 &gpioc 0x0 0x0 >, < 0x6 0x0 &gpioa 0x3 0x0 >, < 0x7 0x0 &gpioa 0x2 0x0 >, < 0x8 0x0 &gpioa 0xa 0x0 >, < 0x9 0x0 &gpiob 0x3 0x0 >, < 0xa 0x0 &gpiob 0x5 0x0 >, < 0xb 0x0 &gpiob 0x4 0x0 >, < 0xc 0x0 &gpiob 0xa 0x0 >, < 0xd 0x0 &gpioa 0x8 0x0 >, < 0xe 0x0 &gpioa 0x9 0x0 >, < 0xf 0x0 &gpioc 0x7 0x0 >, < 0x10 0x0 &gpiob 0x6 0x0 >, < 0x11 0x0 &gpioa 0x7 0x0 >, < 0x12 0x0 &gpioa 0x6 0x0 >, < 0x13 0x0 &gpioa 0x5 0x0 >, < 0x14 0x0 &gpiob 0x9 0x0 >, < 0x15 0x0 &gpiob 0x8 0x0 >;
	};
	leds {
		compatible = "gpio-leds";
		green_led_2: led_2 {
			gpios = < &gpioa 0x5 0x0 >;
			label = "User LD2";
		};
	};
	gpio_keys {
		compatible = "gpio-keys";
		user_button: button {
			label = "User";
			gpios = < &gpioc 0xd 0x1 >;
		};
	};
};
